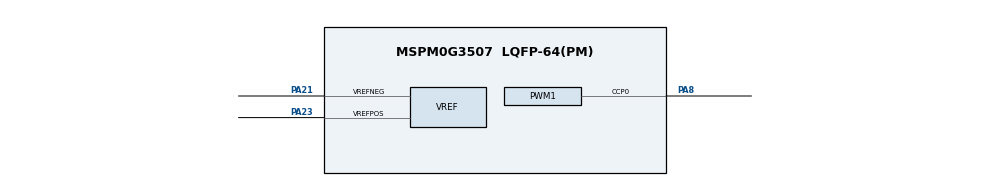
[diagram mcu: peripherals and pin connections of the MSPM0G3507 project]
/**
 * These arguments were used when this file was generated. They will be automatically applied on subsequent loads
 * via the GUI or CLI. Run CLI with '--help' for additional information on how to override these arguments.
 */
//@cliArgs --device "MSPM0G350X" --package "LQFP-64(PM)" --part "Default"
//@v2CliArgs --device "MSPM0G3507" --package "LQFP-64(PM)"
// @cliArgs --board /ti/boards/LP_MSPM0G3507 --rtos nortos

/**
 * Import the modules used in this configuration.
 */
const DAC12  = scripting.addModule("/ti/driverlib/DAC12");
const PWM    = scripting.addModule("/ti/driverlib/PWM", {}, false);
const PWM1   = PWM.addInstance();
const SYSCTL = scripting.addModule("/ti/driverlib/SYSCTL");
const VREF   = scripting.addModule("/ti/driverlib/VREF");

/**
 * Write custom configuration values to the imported modules.
 */
const gate8  = system.clockTree["MFPCLKGATE"];
gate8.enable = true;

DAC12.dacOutputPinEn = true;
DAC12.dacAmplifier   = "ON";
DAC12.dacPosVREF     = "VEREFP";
DAC12.dacNegVREF     = "VEREFN";

/*
 * PWM_0 — CC0 channel driving native CCP0 + CCP0N outputs.
 *   CCP0  (PA8)  -> Q2b gate (dummy path): HIGH = dummy ON
 *   CCP0N (PA22) -> Q2a gate (laser path): HIGH = laser ON
 *
 * CCP0N is the intrinsic complement of CCP0 from the CC0 subblock —
 * not the deadband generator — so both pins flip on the same compare
 * event with zero guard band. Current always has a path through either
 * Q2a or Q2b; no current transient at the laser diode.
 *
 * Clock: BUSCLK = 32 MHz, prescale = 1 -> 32 MHz timer clock
 * Period: 3200 counts -> 10 kHz
 * Duty cycle: laser ON = 10% -> CCP0N HIGH 10% -> CCP0 HIGH 90%
 *   ccValue = 3200 * 0.90 = 2880
 */
PWM1.$name                           = "PWM_0";
PWM1.ccIndex                         = [0];
PWM1.ccIndexCmpl                     = [0];
PWM1.clockSource                     = "BUSCLK";
PWM1.clockPrescale                   = 1;
PWM1.timerCount                      = 3199;
PWM1.pwmMode                         = "EDGE_ALIGN";
PWM1.enableShadowLoad                = true;
PWM1.peripheral.$assign              = "TIMA0";
PWM1.peripheral.ccp0Pin.$assign      = "PA8";
PWM1.peripheral.ccp0Pin_cmpl.$assign = "PA22";
PWM1.PWM_CHANNEL_0.$name             = "ti_driverlib_pwm_PWMTimerCC0";
PWM1.PWM_CHANNEL_0.ccValue           = 2880;
PWM1.PWM_CHANNEL_0.shadowUpdateMode  = "ZERO_EVT";

const Board = scripting.addModule("/ti/driverlib/Board", {}, false);

SYSCTL.MFPCLKEn    = true;
SYSCTL.forceDefaultClkConfig = true;
SYSCTL.clockTreeEn  = true;

VREF.basicVrefPins                 = "VREF+-";
VREF.basicIntVolt                  = "DL_VREF_BUFCONFIG_OUTPUT_2_5V";
VREF.checkVREFReady                = true;
VREF.advClockConfigEnable          = true;
VREF.advClkSrc                     = "DL_VREF_CLOCK_BUSCLK";
VREF.peripheral.$assign            = "VREF";
VREF.peripheral.vrefPosPin.$assign = "PA23";
VREF.peripheral.vrefNegPin.$assign = "PA21";
